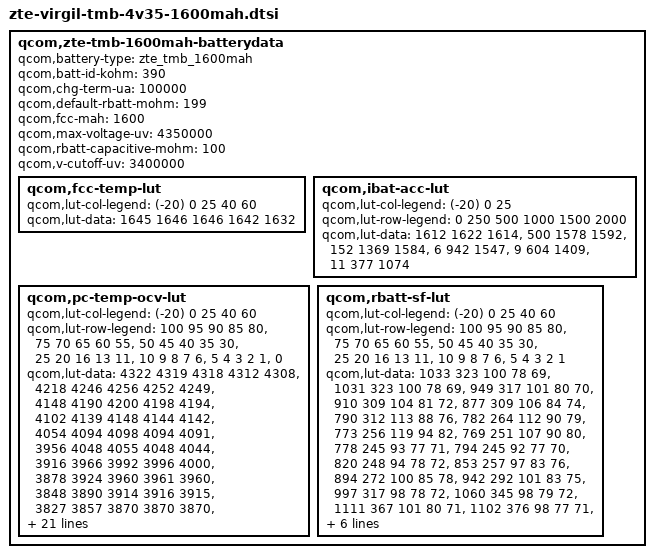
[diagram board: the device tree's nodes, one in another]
/* Copyright (c) 2014, The Linux Foundation. All rights reserved.
*
* This program is free software; you can redistribute it and/or modify
* it under the terms of the GNU General Public License version 2 and
* only version 2 as published by the Free Software Foundation.
*
* This program is distributed in the hope that it will be useful,
* but WITHOUT ANY WARRANTY; without even the implied warranty of
* MERCHANTABILITY or FITNESS FOR A PARTICULAR PURPOSE.  See the
* GNU General Public License for more details.
*/

qcom,zte-tmb-1600mah-batterydata {
	qcom,battery-type = "zte_tmb_1600mah";
	qcom,batt-id-kohm = <390>;
	qcom,chg-term-ua = <100000>;
	qcom,default-rbatt-mohm = <199>;
	qcom,fcc-mah = <1600>;
	qcom,max-voltage-uv = <4350000>;
	qcom,rbatt-capacitive-mohm = <100>;
	qcom,v-cutoff-uv = <3400000>;

	qcom,fcc-temp-lut {
		qcom,lut-col-legend = <(-20) 0 25 40 60>;
		qcom,lut-data = <1645 1646 1646 1642 1632>;
	};

	qcom,ibat-acc-lut {
		qcom,lut-col-legend = <(-20) 0 25>;
		qcom,lut-row-legend = <0 250 500 1000 1500 2000>;
		qcom,lut-data = <1612 1622 1614>,
				<500 1578 1592>,
				<152 1369 1584>,
				<6 942 1547>,
				<9 604 1409>,
				<11 377 1074>;
	};

	qcom,pc-temp-ocv-lut {
		qcom,lut-col-legend = <(-20) 0 25 40 60>;
		qcom,lut-row-legend = <100 95 90 85 80>,
					<75 70 65 60 55>,
					<50 45 40 35 30>,
					<25 20 16 13 11>,
					<10 9 8 7 6>,
					<5 4 3 2 1>,
					<0>;
		qcom,lut-data = <4322 4319 4318 4312 4308>,
				<4218 4246 4256 4252 4249>,
				<4148 4190 4200 4198 4194>,
				<4102 4139 4148 4144 4142>,
				<4054 4094 4098 4094 4091>,
				<3956 4048 4055 4048 4044>,
				<3916 3966 3992 3996 4000>,
				<3878 3924 3960 3961 3960>,
				<3848 3890 3914 3916 3915>,
				<3827 3857 3870 3870 3870>,
				<3811 3830 3842 3842 3842>,
				<3798 3809 3820 3820 3819>,
				<3785 3794 3801 3802 3800>,
				<3773 3784 3786 3786 3784>,
				<3761 3775 3772 3768 3761>,
				<3749 3763 3756 3746 3734>,
				<3735 3746 3737 3727 3714>,
				<3722 3726 3717 3707 3692>,
				<3710 3708 3696 3687 3675>,
				<3700 3700 3690 3682 3670>,
				<3694 3698 3690 3682 3670>,
				<3686 3695 3688 3680 3668>,
				<3677 3692 3686 3678 3665>,
				<3665 3688 3682 3674 3659>,
				<3646 3676 3669 3658 3641>,
				<3618 3649 3638 3624 3606>,
				<3578 3605 3592 3576 3558>,
				<3514 3544 3530 3514 3498>,
				<3419 3460 3449 3434 3417>,
				<3268 3333 3320 3308 3286>,
				<3000 3000 3000 3000 3000>;
	};

	qcom,rbatt-sf-lut {
		qcom,lut-col-legend = <(-20) 0 25 40 60>;
		qcom,lut-row-legend = <100 95 90 85 80>,
					<75 70 65 60 55>,
					<50 45 40 35 30>,
					<25 20 16 13 11>,
					<10 9 8 7 6>,
					<5 4 3 2 1>;
		qcom,lut-data = <1033 323 100 78 69>,
				<1031 323 100 78 69>,
				<949 317 101 80 70>,
				<910 309 104 81 72>,
				<877 309 106 84 74>,
				<790 312 113 88 76>,
				<782 264 112 90 79>,
				<773 256 119 94 82>,
				<769 251 107 90 80>,
				<778 245 93 77 71>,
				<794 245 92 77 70>,
				<820 248 94 78 72>,
				<853 257 97 83 76>,
				<894 272 100 85 78>,
				<942 292 101 83 75>,
				<997 317 98 78 72>,
				<1060 345 98 79 72>,
				<1111 367 101 80 71>,
				<1102 376 98 77 71>,
				<1114 390 99 78 72>,
				<1139 402 102 80 73>,
				<1166 417 106 83 74>,
				<1193 436 109 85 74>,
				<1221 455 112 86 75>,
				<1257 472 113 85 74>,
				<1332 485 111 83 73>,
				<1455 508 114 84 75>,
				<1727 545 119 89 79>,
				<2253 593 130 98 85>,
				<4507 904 175 129 105>;
	};
};
